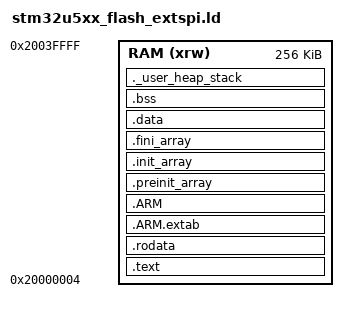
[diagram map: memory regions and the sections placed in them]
/*
*****************************************************************************
**
**  File        : stm32u5xx_flash_extspi.ld
**
**  Abstract    : Linker script for STM32U5xx External Loader
**
*****************************************************************************
*/

/* Entry Point */
ENTRY(Init)

/* Memory Regions for External Loader (RAM only execution) */
MEMORY
{
  RAM (xrw)   : ORIGIN = 0x20000004, LENGTH = 256K - 4
}

/* Sections */
SECTIONS
{
  /* The program code and other data into RAM memory */
  .text :
  {
    . = ALIGN(4);
    *(.text)           /* .text sections (code) */
    *(.text*)          /* .text* sections (code) */
    *(.glue_7)         /* glue arm to thumb code */
    *(.glue_7t)        /* glue thumb to arm code */
    *(.eh_frame)

    KEEP (*(.init))
    KEEP (*(.fini))

    . = ALIGN(4);
    _etext = .;        /* define a global symbols at end of code */
  } >RAM

  /* Constant data into RAM memory */
  .rodata :
  {
    . = ALIGN(4);
    *(.rodata)         /* .rodata sections (constants, strings, etc.) */
    *(.rodata*)        /* .rodata* sections (constants, strings, etc.) */
    . = ALIGN(4);
  } >RAM

  .ARM.extab   : { *(.ARM.extab* .gnu.linkonce.armextab.*) } >RAM
  .ARM : {
    __exidx_start = .;
    *(.ARM.exidx*)
    __exidx_end = .;
  } >RAM

  .preinit_array     :
  {
    PROVIDE_HIDDEN (__preinit_array_start = .);
    KEEP (*(.preinit_array*))
    PROVIDE_HIDDEN (__preinit_array_end = .);
  } >RAM
  
  .init_array :
  {
    PROVIDE_HIDDEN (__init_array_start = .);
    KEEP (*(SORT(.init_array.*)))
    KEEP (*(.init_array*))
    PROVIDE_HIDDEN (__init_array_end = .);
  } >RAM
  
  .fini_array :
  {
    PROVIDE_HIDDEN (__fini_array_start = .);
    KEEP (*(SORT(.fini_array.*)))
    KEEP (*(.fini_array*))
    PROVIDE_HIDDEN (__fini_array_end = .);
  } >RAM

  /* Used by the startup to initialize data */
  _sidata = LOADADDR(.data);

  /* Initialized data sections into RAM memory */
  .data :
  {
    . = ALIGN(4);
    _sdata = .;        /* create a global symbol at data start */
    *(.data)           /* .data sections */
    *(.data*)          /* .data* sections */

    . = ALIGN(4);
    _edata = .;        /* define a global symbol at data end */
  } >RAM

  /* Uninitialized data section into RAM memory */
  . = ALIGN(4);
  .bss :
  {
    /* This is used by the startup in order to initialize the .bss section */
    _sbss = .;         /* define a global symbol at bss start */
    __bss_start__ = _sbss;
    *(.bss)
    *(.bss*)
    *(COMMON)

    . = ALIGN(4);
    _ebss = .;         /* define a global symbol at bss end */
    __bss_end__ = _ebss;
  } >RAM

  /* User_heap_stack section, used to check that there is enough RAM left */
  ._user_heap_stack :
  {
    . = ALIGN(8);
    PROVIDE ( end = . );
    PROVIDE ( _end = . );
    . = . + 0x400;     /* Minimum stack size */
    . = . + 0x400;     /* Minimum heap size */
    . = ALIGN(8);
  } >RAM

  /* Remove information from the compiler libraries */
  /DISCARD/ :
  {
    libc.a ( * )
    libm.a ( * )
    libgcc.a ( * )
  }

  .ARM.attributes 0 : { *(.ARM.attributes) }
}
